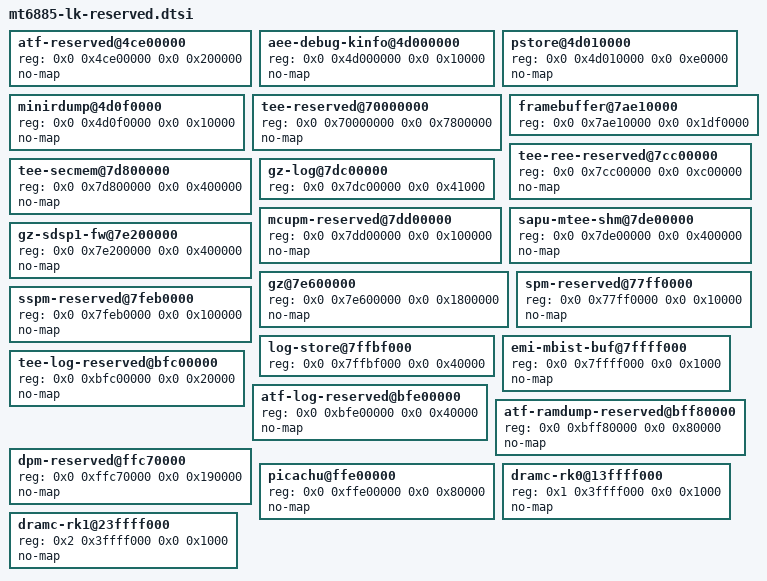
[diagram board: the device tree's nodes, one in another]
/* generated by gen-reserved.py from lk's runtime DTB - do not edit */
		atf-reserved@4ce00000 {
			reg = <0x0 0x4ce00000 0x0 0x200000>;
			no-map;
		};

		aee-debug-kinfo@4d000000 {
			reg = <0x0 0x4d000000 0x0 0x10000>;
			no-map;
		};

		pstore@4d010000 {
			reg = <0x0 0x4d010000 0x0 0xe0000>;
			no-map;
		};

		minirdump@4d0f0000 {
			reg = <0x0 0x4d0f0000 0x0 0x10000>;
			no-map;
		};

		tee-reserved@70000000 {
			reg = <0x0 0x70000000 0x0 0x7800000>;
			no-map;
		};

		framebuffer@7ae10000 {
			reg = <0x0 0x7ae10000 0x0 0x1df0000>;
		};

		tee-ree-reserved@7cc00000 {
			reg = <0x0 0x7cc00000 0x0 0xc00000>;
			no-map;
		};

		tee-secmem@7d800000 {
			reg = <0x0 0x7d800000 0x0 0x400000>;
			no-map;
		};

		gz-log@7dc00000 {
			reg = <0x0 0x7dc00000 0x0 0x41000>;
		};

		mcupm-reserved@7dd00000 {
			reg = <0x0 0x7dd00000 0x0 0x100000>;
			no-map;
		};

		sapu-mtee-shm@7de00000 {
			reg = <0x0 0x7de00000 0x0 0x400000>;
			no-map;
		};

		gz-sdsp1-fw@7e200000 {
			reg = <0x0 0x7e200000 0x0 0x400000>;
			no-map;
		};

		gz@7e600000 {
			reg = <0x0 0x7e600000 0x0 0x1800000>;
			no-map;
		};

		/*
		 * lk copies spm_firmware.bin (spmfw partition) here on every boot,
		 * but only lists it in a normal boot's DT ("SPM-reserved")
		 */
		spm-reserved@77ff0000 {
			reg = <0x0 0x77ff0000 0x0 0x10000>;
			no-map;
		};

		sspm-reserved@7feb0000 {
			reg = <0x0 0x7feb0000 0x0 0x100000>;
			no-map;
		};

		log-store@7ffbf000 {
			reg = <0x0 0x7ffbf000 0x0 0x40000>;
		};

		emi-mbist-buf@7ffff000 {
			reg = <0x0 0x7ffff000 0x0 0x1000>;
			no-map;
		};

		tee-log-reserved@bfc00000 {
			reg = <0x0 0xbfc00000 0x0 0x20000>;
			no-map;
		};

		atf-log-reserved@bfe00000 {
			reg = <0x0 0xbfe00000 0x0 0x40000>;
			no-map;
		};

		atf-ramdump-reserved@bff80000 {
			reg = <0x0 0xbff80000 0x0 0x80000>;
			no-map;
		};

		dpm-reserved@ffc70000 {
			reg = <0x0 0xffc70000 0x0 0x190000>;
			no-map;
		};

		picachu@ffe00000 {
			reg = <0x0 0xffe00000 0x0 0x80000>;
			no-map;
		};

		dramc-rk0@13ffff000 {
			reg = <0x1 0x3ffff000 0x0 0x1000>;
			no-map;
		};

		dramc-rk1@23ffff000 {
			reg = <0x2 0x3ffff000 0x0 0x1000>;
			no-map;
		};

